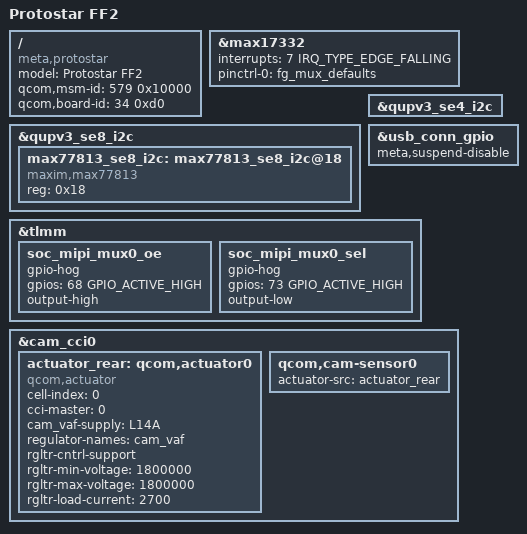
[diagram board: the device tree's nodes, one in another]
/dts-v1/;
/plugin/;

#include "greatwhite.dtsi"

/ {
	model = "Protostar FF2";
	compatible = "meta,protostar", "meta,protostar-dev0";
	qcom,msm-id = <579 0x10000>;
	qcom,board-id = <34 0xd0>;
};

&max17332 {
	interrupts = <7 IRQ_TYPE_EDGE_FALLING>;
	pinctrl-names = "default";
	pinctrl-0 = <&fg_mux_defaults>;
};

/delete-node/ &max77813;

&qupv3_se8_i2c {
	max77813_se8_i2c:max77813_se8_i2c@18 {
		compatible = "maxim,max77813";
		reg = <0x18>;
		status = "ok";
	};
};

/* Display card (Celeste) I2C bus: */

&qupv3_se4_i2c {
	status = "ok";
};

&usb_conn_gpio {
	meta,suspend-disable;
};

&tlmm {
  soc_mipi_mux0_oe: soc_mipi_mux0_oe {
    gpio-hog;
    gpios = <68 GPIO_ACTIVE_HIGH>;
    output-high;
  };
  soc_mipi_mux0_sel: soc_mipi_mux0_sel {
    gpio-hog;
    gpios = <73 GPIO_ACTIVE_HIGH>;
    output-low;
  };
};

/* Protostar FF2 */

&cam_cci0 {
  actuator_rear: qcom,actuator0 {
    cell-index = <0>;
    compatible = "qcom,actuator";
    cci-master = <0>;
    cam_vaf-supply = <&L14A>;
    regulator-names = "cam_vaf";
    rgltr-cntrl-support;
    rgltr-min-voltage  = <1800000>;
    rgltr-max-voltage  = <1800000>;
    rgltr-load-current = <2700>;
    status = "ok";
  };

  qcom,cam-sensor0 {
    actuator-src = <&actuator_rear>;
  };
};

#include "meta-neo-action-button.dtsi"
